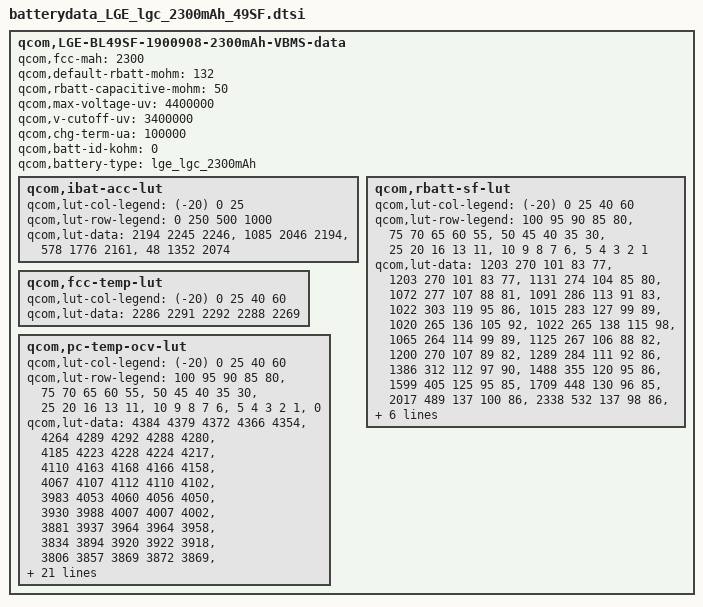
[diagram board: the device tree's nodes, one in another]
 qcom,LGE-BL49SF-1900908-2300mAh-VBMS-data {
	qcom,fcc-mah = <2300>;
	qcom,default-rbatt-mohm = <132>;
	qcom,rbatt-capacitive-mohm = <50>;
	qcom,max-voltage-uv = <4400000>;
	qcom,v-cutoff-uv = <3400000>;
	qcom,chg-term-ua = <100000>;
	qcom,batt-id-kohm = <0>;
	qcom,battery-type = "lge_lgc_2300mAh";

	qcom,ibat-acc-lut {
		qcom,lut-col-legend = <(-20) 0 25>;
		qcom,lut-row-legend = <0 250 500 1000>;
		qcom,lut-data = <2194 2245 2246>,
				<1085 2046 2194>,
				<578 1776 2161>,
				<48 1352 2074>;
	};

	qcom,rbatt-sf-lut {
		qcom,lut-col-legend = <(-20) 0 25 40 60>;
		qcom,lut-row-legend = <100 95 90 85 80>,
				<75 70 65 60 55>,
				<50 45 40 35 30>,
				<25 20 16 13 11>,
				<10 9 8 7 6>,
				<5 4 3 2 1>;
		qcom,lut-data = <1203 270 101 83 77>,
				<1203 270 101 83 77>,
				<1131 274 104 85 80>,
				<1072 277 107 88 81>,
				<1091 286 113 91 83>,
				<1022 303 119 95 86>,
				<1015 283 127 99 89>,
				<1020 265 136 105 92>,
				<1022 265 138 115 98>,
				<1065 264 114 99 89>,
				<1125 267 106 88 82>,
				<1200 270 107 89 82>,
				<1289 284 111 92 86>,
				<1386 312 112 97 90>,
				<1488 355 120 95 86>,
				<1599 405 125 95 85>,
				<1709 448 130 96 85>,
				<2017 489 137 100 86>,
				<2338 532 137 98 86>,
				<2482 551 145 103 88>,
				<2270 526 148 106 91>,
				<2076 518 154 108 92>,
				<2329 539 162 112 92>,
				<2608 556 171 115 94>,
				<3067 570 178 117 93>,
				<3805 584 186 120 96>,
				<5010 605 200 130 104>,
				<7007 630 218 139 106>,
				<10411 660 237 155 120>,
				<17312 761 270 192 150>;
	};

	qcom,fcc-temp-lut {
		qcom,lut-col-legend = <(-20) 0 25 40 60>;
		qcom,lut-data = <2286 2291 2292 2288 2269>;
	};

	qcom,pc-temp-ocv-lut {
		qcom,lut-col-legend = <(-20) 0 25 40 60>;
		qcom,lut-row-legend = <100 95 90 85 80>,
				<75 70 65 60 55>,
				<50 45 40 35 30>,
				<25 20 16 13 11>,
				<10 9 8 7 6>,
				<5 4 3 2 1>,
				<0>;
		qcom,lut-data = <4384 4379 4372 4366 4354>,
				<4264 4289 4292 4288 4280>,
				<4185 4223 4228 4224 4217>,
				<4110 4163 4168 4166 4158>,
				<4067 4107 4112 4110 4102>,
				<3983 4053 4060 4056 4050>,
				<3930 3988 4007 4007 4002>,
				<3881 3937 3964 3964 3958>,
				<3834 3894 3920 3922 3918>,
				<3806 3857 3869 3872 3869>,
				<3789 3826 3834 3835 3832>,
				<3774 3800 3810 3810 3808>,
				<3759 3784 3790 3791 3788>,
				<3742 3774 3776 3776 3773>,
				<3722 3764 3768 3762 3755>,
				<3700 3745 3756 3748 3734>,
				<3673 3714 3732 3724 3710>,
				<3648 3692 3703 3696 3682>,
				<3614 3680 3679 3673 3662>,
				<3592 3672 3670 3665 3652>,
				<3579 3666 3667 3662 3650>,
				<3564 3660 3664 3658 3646>,
				<3544 3652 3658 3653 3640>,
				<3516 3640 3648 3643 3630>,
				<3479 3617 3628 3622 3604>,
				<3436 3584 3592 3584 3564>,
				<3388 3542 3544 3536 3516>,
				<3330 3480 3482 3472 3450>,
				<3257 3390 3396 3386 3360>,
				<3154 3250 3266 3255 3236>,
				<3000 3000 3000 3000 3000>;
	};
};
